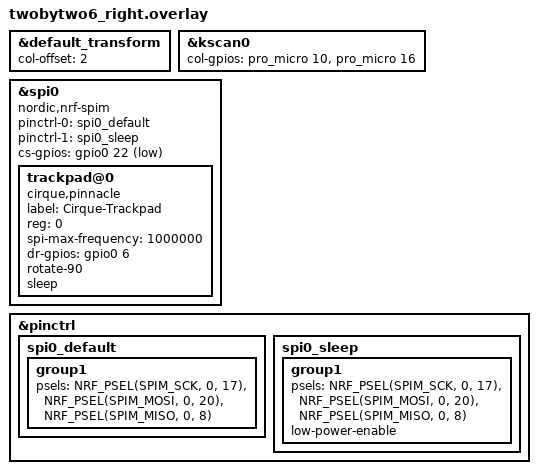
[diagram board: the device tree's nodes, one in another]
#include "twobytwo6.dtsi" // Notice that the main dtsi files are included in the overlay.

&default_transform { // The matrix transform for this board is 2 columns over because the left half is 2 columns wide according to the matrix.
  col-offset = <2>;
};

&kscan0 {
  col-gpios
    = <&pro_micro 10 (GPIO_ACTIVE_HIGH | GPIO_PULL_DOWN)>
    , <&pro_micro 16 (GPIO_ACTIVE_HIGH | GPIO_PULL_DOWN)>
  ;
};

&spi0 {
  compatible = "nordic,nrf-spim";
  status = "okay";
  pinctrl-0 = <&spi0_default>;
  pinctrl-1 = <&spi0_sleep>;
  pinctrl-names = "default", "sleep";
  cs-gpios = <&gpio0 22 GPIO_ACTIVE_LOW>;
  trackpad@0 {
    compatible = "cirque,pinnacle";
    status = "okay";
    label = "Cirque-Trackpad";
    reg = <0>;
    spi-max-frequency = <1000000>;
    dr-gpios = <&gpio0 6 GPIO_ACTIVE_HIGH>;
    rotate-90;
    sleep;
  };
};

&pinctrl {
  spi0_default: spi0_default {
    group1 {
      psels = <NRF_PSEL(SPIM_SCK, 0, 17)>,
              <NRF_PSEL(SPIM_MOSI, 0, 20)>,
              <NRF_PSEL(SPIM_MISO, 0, 8)>;
    };
  };
  spi0_sleep: spi0_sleep {
    group1 {
      psels = <NRF_PSEL(SPIM_SCK, 0, 17)>,
              <NRF_PSEL(SPIM_MOSI, 0, 20)>,
              <NRF_PSEL(SPIM_MISO, 0, 8)>;
              low-power-enable;
    };
  };
};
